AUTOSAR XML (schema 4-2-2)
package /ComponentTypes
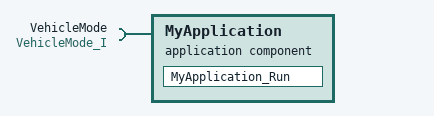
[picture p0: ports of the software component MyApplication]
  application sw component type MyApplication
    require port VehicleMode: mode-switch-receiver-com-spec{enhanced-mode-api=false, mode-group=mode, supports-asynchronous-mode-switch=false}, required-interface=VehicleMode_I
    behavior MyApplication_InternalBehavior: port-api-option{enable-take-address=false, indirect-api=false, port=VehicleMode}
      runnable MyApplication_Run: mode-access-point=VehicleMode.mode
  swc implementation MyApplication_Implementation: behavior=MyApplication_InternalBehavior
